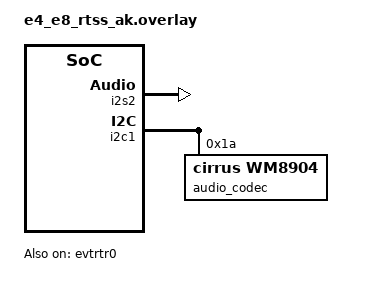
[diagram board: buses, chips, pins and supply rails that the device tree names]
/* Copyright (C) Alif Semiconductor - All Rights Reserved.
 * Use, distribution and modification of this code is permitted under the
 * terms stated in the Alif Semiconductor Software License Agreement
 *
 * You should have received a copy of the Alif Semiconductor Software
 * License Agreement with this file. If not, please write to:
 * contact@alifsemi.com, or visit: https://alifsemi.com/license
 *
 */
#include <zephyr/dt-bindings/dma/alif_dma_event_router.h>
/ {
	aliases {
		i2s-codec-tx = &i2s2;
	};
};

&dma0 {
	status = "okay";
};
&evtrtr0 {
	status = "okay";
};
&i2s2 {
	/*
	 * Cell 0: ALIF_DMA_ENCODE(channel, dma_group, handshake)
	 *   - channel: Physical DMA channel (0 for TX)
	 *   - dma_group: Input source selection (1)
	 *   - handshake: Enable hardware handshaking (1 for I2S)
	 * Cell 1: Peripheral request number (30 for TX)
	 */
	dmas = <&evtrtr0 ALIF_DMA_ENCODE(0, 1, 1) 30>;
	dma-names = "txdma";
	status = "okay";
};

&i2c1 {
	status = "okay";

	audio_codec: wm8904@1a {
		compatible = "cirrus,wm8904";
		reg = <0x1a>;
		status = "okay";
	};
};
